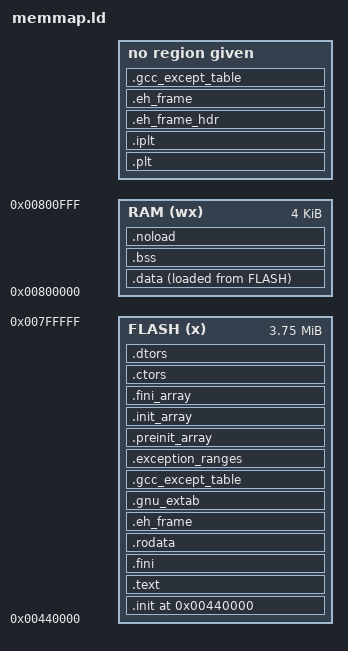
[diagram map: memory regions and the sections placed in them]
/* Script for -z combreloc: combine and sort reloc sections */
/* Copyright (C) 2014-2017 Free Software Foundation, Inc.
   Copying and distribution of this script, with or without modification,
   are permitted in any medium without royalty provided the copyright
   notice and this notice are preserved.  */

/* Modified from GCC default for hazard5 testbench */

MEMORY
  {
    /* First 256K of flash is left for a couple of FPGA images */
    FLASH (x)  : ORIGIN = 4M + 256K, LENGTH = 4M - 256K
    RAM   (wx) : ORIGIN = 8M, LENGTH = 4K
  }

OUTPUT_FORMAT("elf32-littleriscv", "elf32-littleriscv",
        "elf32-littleriscv")
OUTPUT_ARCH(riscv)
ENTRY(_start)
SEARCH_DIR("/opt/riscv/riscv32-unknown-elf/lib");
SECTIONS
{
  /* Read-only sections, merged into text segment: */
  PROVIDE (__executable_start = ORIGIN(FLASH)); . = ORIGIN(FLASH);
  .init           :
  {
    KEEP (*(SORT_NONE(.init)))
  } > FLASH
  .plt            : { *(.plt) }
  .iplt           : { *(.iplt) }
  .text           :
  {
    *(.vectors)
    *(.text.unlikely .text.*_unlikely .text.unlikely.*)
    *(.text.exit .text.exit.*)
    *(.text.startup .text.startup.*)
    *(.text.hot .text.hot.*)
    *(.text .stub .text.* .gnu.linkonce.t.*)
    /* .gnu.warning sections are handled specially by elf32.em.  */
    *(.gnu.warning)
  } > FLASH
  .fini           :
  {
    KEEP (*(SORT_NONE(.fini)))
  } > FLASH
  PROVIDE (__etext = .);
  PROVIDE (_etext = .);
  PROVIDE (etext = .);
  .rodata         : {
    *(.rodata .rodata.* .gnu.linkonce.r.*)
    *(.rodata1)
  } > FLASH
  .eh_frame_hdr : { *(.eh_frame_hdr) *(.eh_frame_entry .eh_frame_entry.*) }
  .eh_frame       : ONLY_IF_RO { KEEP (*(.eh_frame)) *(.eh_frame.*) }
  .gcc_except_table   : ONLY_IF_RO { *(.gcc_except_table
  .gcc_except_table.*) }
  .gnu_extab   : ONLY_IF_RO { *(.gnu_extab*) }
  /* Exception handling  */
  .eh_frame       : ONLY_IF_RW { KEEP (*(.eh_frame)) *(.eh_frame.*) } > FLASH
  .gnu_extab      : ONLY_IF_RW { *(.gnu_extab) } > FLASH
  .gcc_except_table   : ONLY_IF_RW { *(.gcc_except_table .gcc_except_table.*) } > FLASH
  .exception_ranges   : ONLY_IF_RW { *(.exception_ranges .exception_ranges*) } > FLASH
  .preinit_array     :
  {
    PROVIDE_HIDDEN (__preinit_array_start = .);
    KEEP (*(.preinit_array))
    PROVIDE_HIDDEN (__preinit_array_end = .);
  } > FLASH
  .init_array     :
  {
    PROVIDE_HIDDEN (__init_array_start = .);
    KEEP (*(SORT_BY_INIT_PRIORITY(.init_array.*) SORT_BY_INIT_PRIORITY(.ctors.*)))
    KEEP (*(.init_array EXCLUDE_FILE (*crtbegin.o *crtbegin?.o *crtend.o *crtend?.o ) .ctors))
    PROVIDE_HIDDEN (__init_array_end = .);
  } > FLASH
  .fini_array     :
  {
    PROVIDE_HIDDEN (__fini_array_start = .);
    KEEP (*(SORT_BY_INIT_PRIORITY(.fini_array.*) SORT_BY_INIT_PRIORITY(.dtors.*)))
    KEEP (*(.fini_array EXCLUDE_FILE (*crtbegin.o *crtbegin?.o *crtend.o *crtend?.o ) .dtors))
    PROVIDE_HIDDEN (__fini_array_end = .);
  } > FLASH
  .ctors          :
  {
    /* gcc uses crtbegin.o to find the start of
       the constructors, so we make sure it is
       first.  Because this is a wildcard, it
       doesn't matter if the user does not
       actually link against crtbegin.o; the
       linker won't look for a file to match a
       wildcard.  The wildcard also means that it
       doesn't matter which directory crtbegin.o
       is in.  */
    KEEP (*crtbegin.o(.ctors))
    KEEP (*crtbegin?.o(.ctors))
    /* We don't want to include the .ctor section from
       the crtend.o file until after the sorted ctors.
       The .ctor section from the crtend file contains the
       end of ctors marker and it must be last */
    KEEP (*(EXCLUDE_FILE (*crtend.o *crtend?.o ) .ctors))
    KEEP (*(SORT(.ctors.*)))
    KEEP (*(.ctors))
  } > FLASH
  .dtors          :
  {
    KEEP (*crtbegin.o(.dtors))
    KEEP (*crtbegin?.o(.dtors))
    KEEP (*(EXCLUDE_FILE (*crtend.o *crtend?.o ) .dtors))
    KEEP (*(SORT(.dtors.*)))
    KEEP (*(.dtors))
  } > FLASH
  __data_load_src = .;
  .data           :
  {
    . = ALIGN(4);
    __data_load_dst = .;
    *(.data .data.* .gnu.linkonce.d.*)
    . = ALIGN(4);
    *(.time_critical .time_critical.*)
    SORT(CONSTRUCTORS)
    *(.data1)
    __global_pointer$ = . + 0x800;
    *(.srodata.cst16) *(.srodata.cst8) *(.srodata.cst4) *(.srodata.cst2) *(.srodata .srodata.*)
    *(.sdata .sdata.* .gnu.linkonce.s.*)
    . = ALIGN(4);
    __data_load_dst_end = .;
  } > RAM AT> FLASH
  _edata = .; PROVIDE (edata = .);
  . = .;
  __bss_start = .;
  .bss            :
  {
    *(.dynsbss)
    *(.sbss .sbss.* .gnu.linkonce.sb.*)
    *(.scommon)
    *(.dynbss)
    *(.bss .bss.* .gnu.linkonce.b.*)
    *(COMMON)
   . = ALIGN(. != 0 ? 32 / 8 : 1);
  } > RAM
  . = ALIGN(32 / 8);
  . = SEGMENT_START("ldata-segment", .);
  . = ALIGN(32 / 8);
  __bss_end = .;
  .noload (NOLOAD):
  {
    *(.noload .noload.*)
  } > RAM
  _end = .; PROVIDE (end = .);

  PROVIDE(__stack_top = ORIGIN(RAM) + LENGTH(RAM));
}


